# STM32F0x0 register map
File version: 1.2
CPU: CM0 r0p0, little endian, no MPU, no FPU, 3 interrupt priority bits
Registers are 32-bit, read-write, reset 0x0 unless marked. A register's access mark holds for its fields unless they carry their own. Offsets are from the block's base; lines under a group give offsets from that group; [hi:lo] are bit positions; {n}, {i} and the like mark numbered series; 'fields as' and 'values as' point back to an identical list; <NAME> marks a mode.

## Memory map
0x40000400 TIM3 size 0x400 — General-purpose-timers
0x40001000 TIM6 size 0x400 — Basic-timers
0x40001400 TIM7 size 0x400
0x40002000 TIM14 size 0x400 — General-purpose-timers
0x40002800 RTC size 0x400 — Real-time clock
0x40002C00 WWDG size 0x400 — Window watchdog
0x40003000 IWDG size 0x400 — Independent watchdog
0x40003800 SPI2 size 0x400
0x40004400 USART2 size 0x400
0x40004800 USART3 size 0x400
0x40004C00 USART4 size 0x400
0x40005000 USART5 size 0x400
0x40005400 I2C1 size 0x400 — Inter-integrated circuit
0x40005800 I2C2 size 0x400
0x40005C00 USB size 0x400 — Universal serial bus full-speed device interface
0x40007000 PWR size 0x400 — Power control
0x40010000 SYSCFG size 0x400 — System configuration controller
0x40010400 EXTI size 0x400 — External interrupt/event controller
0x40011400 USART6 size 0x400
0x40012400 ADC size 0x400 — Analog-to-digital converter
0x40012C00 TIM1 size 0x400 — Advanced-timers
0x40013000 SPI1 size 0x400 — Serial peripheral interface
0x40013800 USART1 size 0x400 — Universal synchronous asynchronous receiver transmitter
0x40014000 TIM15 size 0x400 — General-purpose-timers
0x40014400 TIM16 size 0x400 — General-purpose-timers
0x40014800 TIM17 size 0x400
0x40015800 DBGMCU size 0x400 — Debug support
0x40020000 DMA1 size 0x400 — DMA controller
0x40021000 RCC size 0x400 — Reset and clock control
0x40022000 Flash size 0x400
0x40023000 CRC size 0x400 — cyclic redundancy check calculation unit
0x48000000 GPIOA size 0x400 — General-purpose I/Os
0x48000400 GPIOB size 0x400 — General-purpose I/Os
0x48000800 GPIOC size 0x400
0x48000C00 GPIOD size 0x400
0x48001400 GPIOF size 0x400
0xE000E010 STK size 0x11 — SysTick timer
0xE000E100 NVIC size 0x33D — Nested Vectored Interrupt Controller
0xE000ED00 SCB size 0x41 — System control block

## Interrupts
0 WWDG — Window Watchdog interrupt
1 PVD (EXTI) — PVD and VDDIO2 supply comparator interrupt
2 RTC — RTC interrupts
3 FLASH (Flash) — Flash global interrupt
4 RCC — RCC global interruptr
5 EXTI0_1 (EXTI) — EXTI Line[1:0] interrupts
6 EXTI2_3 (EXTI) — EXTI Line[3:2] interrupts
7 EXTI4_15 (EXTI) — EXTI Line15 and EXTI4 interrupts
9 DMA1_CH1 (DMA1) — DMA1 channel 1 interrupt
10 DMA1_CH2_3 (DMA1) — DMA1 channel 2 and 3 interrupt
11 DMA1_CH4_5 (DMA1) — DMA1 channel 4 and 5 interrupt
12 ADC — ADC interrupt
13 TIM1_BRK_UP_TRG_COM (TIM1) — TIM1 break, update, trigger and commutation upt
14 TIM1_CC (TIM1) — TIM1 Capture Compare interrupt
16 TIM3 — TIM3 global interrupt
17 TIM6 — TIM6 global interrupt
19 TIM14 — TIM14 global interrupt
20 TIM15 — TIM15 global interrupt
21 TIM16 — TIM16 global interrupt
22 TIM17 — TIM17 global interrupt
23 I2C1 — I2C1 global interrupt
24 I2C2 — I2C2 global interrupt
25 SPI1 — SPI1_global_interrupt
26 SPI2 — SPI2 global interrupt
27 USART1 — USART1 global interrupt
28 USART2 — USART2 global interrupt
29 USART3_4_5_6 (USART3) — USART3, USART4, USART5, USART6 global interrupt
31 USB — USB global interrupt

## ADC — Analog-to-digital converter
Base 0x40012400
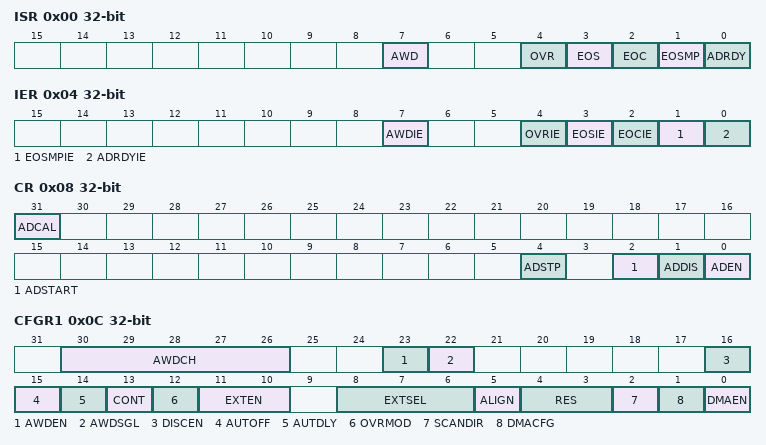
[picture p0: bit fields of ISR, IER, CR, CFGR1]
0x00 ISR — interrupt and status register
  [7] AWD — Analog watchdog flag
  [4] OVR — ADC overrun
  [3] EOS — End of sequence flag
  [2] EOC — End of conversion flag
  [1] EOSMP — End of sampling flag
  [0] ADRDY — ADC ready
0x04 IER — interrupt enable register
  [7] AWDIE — Analog watchdog interrupt enable
  [4] OVRIE — Overrun interrupt enable
  [3] EOSIE — End of conversion sequence interrupt enable
  [2] EOCIE — End of conversion interrupt enable
  [1] EOSMPIE — End of sampling flag interrupt enable
  [0] ADRDYIE — ADC ready interrupt enable
0x08 CR — control register
  [31] ADCAL — ADC calibration
  [4] ADSTP — ADC stop conversion command
  [2] ADSTART — ADC start conversion command
  [1] ADDIS — ADC disable command
  [0] ADEN — ADC enable command
0x0C CFGR1 — configuration register 1
  [30:26] AWDCH — Analog watchdog channel selection
  [23] AWDEN — Analog watchdog enable
  [22] AWDSGL — Enable the watchdog on a single channel or on all channels
  [16] DISCEN — Discontinuous mode
  [15] AUTOFF — Auto-off mode
  [14] AUTDLY — Auto-delayed conversion mode
  [13] CONT — Single / continuous conversion mode
  [12] OVRMOD — Overrun management mode
  [11:10] EXTEN — External trigger enable and polarity selection
  [8:6] EXTSEL — External trigger selection
  [5] ALIGN — Data alignment
  [4:3] RES — Data resolution
  [2] SCANDIR — Scan sequence direction
  [1] DMACFG — Direct memery access configuration
  [0] DMAEN — Direct memory access enable
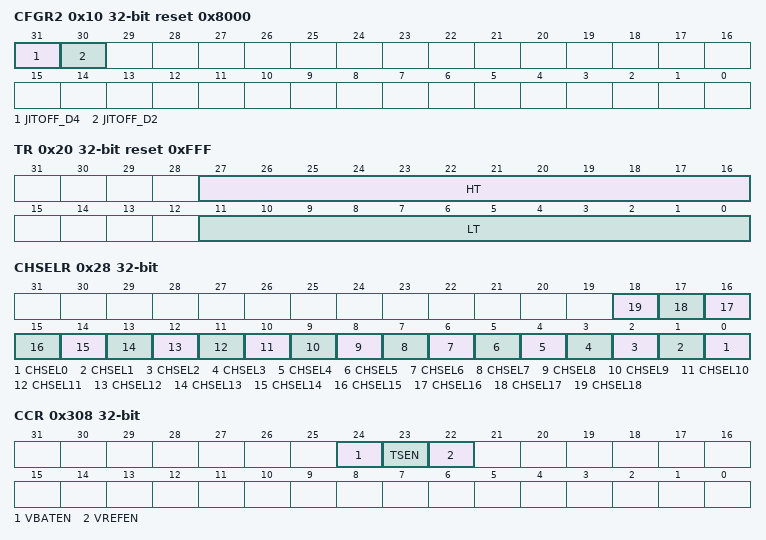
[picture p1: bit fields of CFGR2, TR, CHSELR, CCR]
0x10 CFGR2 reset 0x8000 — configuration register 2
  [31] JITOFF_D4, [30] JITOFF_D2
0x14 SMPR — sampling time register
  [2:0] SMPR — Sampling time selection
0x20 TR reset 0xFFF — watchdog threshold register
  [27:16] HT — Analog watchdog higher threshold
  [11:0] LT — Analog watchdog lower threshold
0x28 CHSELR — channel selection register
  [n] CHSEL{n} (n=0..18) — Channel-x selection
0x40 DR ro — data register
  [15:0] DATA — Converted data
0x308 CCR — common configuration register
  [24] VBATEN — VBAT enable
  [23] TSEN — Temperature sensor enable
  [22] VREFEN — Temperature sensor and VREFINT enable
